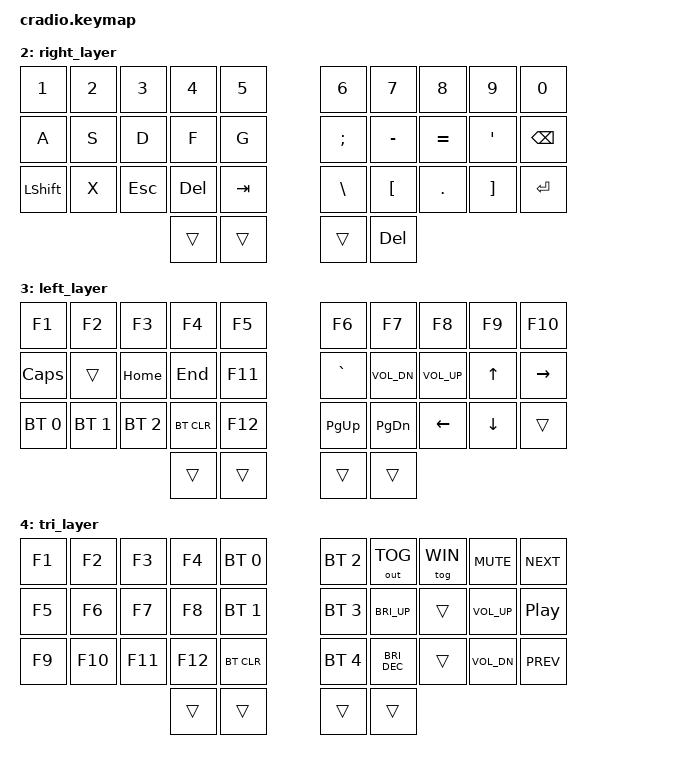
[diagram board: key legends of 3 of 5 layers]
// Copyright (c) 2022 The ZMK Contributors
// SPDX-License-Identifier: MIT

#include <behaviors.dtsi>
#include <dt-bindings/zmk/keys.h>
#include <dt-bindings/zmk/bt.h>
#include <dt-bindings/zmk/outputs.h>

// Home row mods macro
#define HRML(k2,k3,k4) &ht LCTRL k2  &ht LGUI k3  &ht LALT k4
#define HRMR(k1,k2,k3) &ht RALT k1  &ht RGUI k2  &ht RCTRL k3
#define MHRML(k2,k3,k4) &ht LGUI k2  &ht LCTRL k3  &ht LALT k4
#define MHRMR(k1,k2,k3) &ht RALT k1  &ht RCTRL k2  &ht RGUI k3

#define WIN 0
#define MAC 1
#define RIG 2
#define LEF 3
#define TRI 4

/ {
    behaviors {
        ht: hold_tap {
            label = "hold_tap";
            compatible = "zmk,behavior-hold-tap";
            #binding-cells = <2>;
            flavor = "tap-preferred";
            tapping-term-ms = <250>;
            quick-tap-ms = <125>;
            global-quick-tap;
            bindings = <&kp>, <&kp>;
        };
    };

    conditional_layers {
        compatible = "zmk,conditional-layers";
        tri_layer {
            if-layers = <RIG LEF>;
            then-layer = <TRI>;
        };
    };

    keymap {
        compatible = "zmk,keymap";
        default_layer {
            bindings = <
        //╭──────────┬──────────┬──────────┬──────────┬──────────╮   ╭──────────┬──────────┬──────────┬──────────┬──────────╮
        //│  Q       │  W       │  E       │  R       │  T       │   │  Y       │  U       │  I       │  O       │  P       │
            &kp Q      &kp W      &kp E      &kp R      &kp T          &kp Y      &kp U      &kp I      &kp O      &kp P
        //├──────────┼──────────┼──────────┼──────────┼──────────┤   ├──────────┼──────────┼──────────┼──────────┼──────────┤
        //│  A       │  S       │  D       │ F        │  G       │   │  H       │  J       │  K       │  L       │BACKSPACE│
            &kp A       &kp S      &kp D      &kp F      &kp G          &kp H      HRMR(J,        K,           L)   &kp BSPC
        //├──────────┼──────────┼──────────┼──────────┼──────────┤   ├──────────┼──────────┼──────────┼──────────┼──────────┤
        //│  Z       │  X       │  C       │  V       │  B       │   │  N       │  M       │ , <      │ / ？      │ ENTER SHIFT   │
            HRML(Z,        X,           C)          &kp V      &kp B          &kp N      &kp M      &kp COMMA  &kp SLASH    &ht RSHIFT ENTER 
        //╰──────────┴──────────┴──────────┼──────────┼──────────┤   ├──────────┼──────────┼──────────┴──────────┴──────────╯
                                           &kp SPACE          &mo RIG                 &mo RIG       &mo LEF
        //                                 ╰──────────┴──────────╯   ╰──────────┴──────────╯
            >;
        };

        mac_layer {
            bindings = <
        //╭──────────┬──────────┬──────────┬──────────┬──────────╮   ╭──────────┬──────────┬──────────┬──────────┬──────────╮
        //│  Q       │  W       │  E       │  R       │  T       │   │  Y       │  U       │  I       │  O       │  P       │
            &kp Q      &kp W      &kp E      &kp R      &kp T          &kp Y      &kp U      &kp I      &kp O      &kp P
        //├──────────┼──────────┼──────────┼──────────┼──────────┤   ├──────────┼──────────┼──────────┼──────────┼──────────┤
        //│  A       │  S       │  D       │ F       │  G       │   │  H       │  J       │  K       │  L       │BACKSPACE │
            &kp A       &kp S      &kp D      &kp F      &kp G          &kp H      MHRMR(J,        K,           L)   &kp BSPC
        //├──────────┼──────────┼──────────┼──────────┼──────────┤   ├──────────┼──────────┼──────────┼──────────┼──────────┤
        //│  Z       │  X       │  C       │  V       │  B       │   │  N       │  M       │ , <      │ / ？      │ ENTER SHIFT    │
            MHRML(Z,        X,           C)          &kp V      &kp B          &kp N      &kp M      &kp COMMA  &kp SLASH    &ht RSHIFT ENTER
        //╰──────────┴──────────┴──────────┼──────────┼──────────┤   ├──────────┼──────────┼──────────┴──────────┴──────────╯
                                           &kp SPACE          &mo RIG                 &mo RIG       &mo LEF
        //                                 ╰──────────┴──────────╯   ╰──────────┴──────────╯
            >;
        };

        right_layer {
            bindings = <
        //╭──────────┬──────────┬──────────┬──────────┬──────────╮   ╭──────────┬──────────┬──────────┬──────────┬──────────╮
        //│ 1        │  2       │  3       │  4       │  5       │   │ 6        │ 7        │ 8        │ 9        │   0      │
            &kp N1    &kp N2     &kp N3     &kp N4     &kp N5          &kp N6     &kp N7     &kp N8     &kp N9      &kp N0
        //├──────────┼──────────┼──────────┼──────────┼──────────┤   ├──────────┼──────────┼──────────┼──────────┼──────────┤
        //│A        │ S        │ D        │  F       │  G        |   │  ; :       │ - _   │ = +       | ' "      │ BACKSPACE    │
            &kp A       &kp S       &kp D       &kp F        &kp G          &kp SEMI   &kp MINUS   &kp EQUAL  &kp SQT  &kp BSPC
        //├──────────┼──────────┼──────────┼──────────┼──────────┤   ├──────────┼──────────┼──────────┼──────────┼──────────┤
        //│SHIFT │  X       │ ESC        │DELETE     │  TAB        │   │ \ |      │ [ {        │ .>      │ ] }       │ ENTER     │
            &kp LSHIFT   &kp X       &kp ESC       &kp DEL     &kp TAB           &kp BSLH    &kp LBKT   &kp DOT  &kp RBKT  &kp ENTER 
        //╰──────────┴──────────┴──────────┼──────────┼──────────┤   ├──────────┼──────────┼──────────┴──────────┴──────────╯
                                             &trans             &trans                       &trans     &kp DEL
        //                                 ╰──────────┴──────────╯   ╰──────────┴──────────╯
            >;
        };

        left_layer { 
            bindings = <
        //╭──────────┬──────────┬──────────┬───────────┬────────────╮   ╭────────────┬────────────┬──────────┬───────────┬──────────╮
        //│  F1      │  F2      │  F3      │  F4       │ F5                     │   │ F6         │ F7                  │ F8         │ F9           │F10            │
            &kp F1     &kp F2     &kp F3     &kp F4     &kp F5     &kp F6     &kp F7     &kp F8        &kp F9     &kp F10
        //├──────────┼──────────┼──────────┼───────────┼────────────┤   ├────────────┼────────────┼──────────┼───────────┼──────────┤
        //│ CAPSLOCK│           │ HOME    │ END        │ F11        │   │ ` ~       │ VOL_DOWN   │ VOL_UP  │ UP        │  RIGHT        │
            &kp CAPS   &trans  &kp HOME  &kp END  &kp F11 &kp GRAVE   &kp C_VOL_DN   &kp C_VOL_UP   &kp UP  &kp RIGHT
        //├──────────┼──────────┼──────────┼───────────┼────────────┤   ├────────────┼────────────┼──────────┼───────────┼──────────┤
        //│ PROFILE 0 │PROFILE 1 │ PROFILE 2│ CLEAR BT │ F12 │   │PAGE_UP     │ PAGE_DOWN    │ LEFT        |  DOWN    │                │
            &bt BT_SEL 0 &bt BT_SEL 1   &bt BT_SEL 2 &bt BT_CLR &kp F12     &kp PG_UP   &kp PG_DN     &kp LEFT      &kp DOWN      &trans 
        //╰──────────┴──────────┴──────────┼───────────┼────────────┤   ├────────────┼────────────┼──────────┴───────────┴──────────╯
                                                &trans     &trans         &trans     &trans
        //                                  ╰───────────┴──────────╯   ╰──────────┴────────────╯
            >;
        };

        tri_layer {
            bindings = <
        //╭──────────┬──────────┬──────────┬───────────┬────────────╮   ╭────────────┬────────────┬──────────┬───────────┬──────────╮
        //│  F1      │  F2      │  F3      │  F4       │ PROFILE 0  │   │ PROFILE 2  │ TOGGLEOUT  │ WINDOWS  │ VOL MUTE  │ NEXTSONG │
            &kp F1     &kp F2     &kp F3     &kp F4     &bt BT_SEL 0     &bt BT_SEL 2  &out OUT_TOG &tog WIN  &kp C_MUTE  &kp C_NEXT
        //├──────────┼──────────┼──────────┼───────────┼────────────┤   ├────────────┼────────────┼──────────┼───────────┼──────────┤
        //│  F5      │  F6      │  F7      │  F8       │ PROFILE 1  │   │ PROFILE 3  │ INC BRIGHT │          │  VOL UP   │PAUSEMUSIC│
            &kp F5     &kp F6     &kp F7     &kp F8     &bt BT_SEL 1     &bt BT_SEL 3  &kp C_BRI_UP  &trans   &kp C_VOL_UP  &kp C_PP
        //├──────────┼──────────┼──────────┼───────────┼────────────┤   ├────────────┼────────────┼──────────┼───────────┼──────────┤
        //│  F9      │  F10     │  F11     │  F12      │  CLEAR BT  │   │ PROFILE 4  │ DEC BRIGHT │          |  VOL DOWN │ PREVSONG │
            &kp F9     &kp F10    &kp F11    &kp F12     &bt BT_CLR      &bt BT_SEL 4  &kp C_BRI_DEC  &trans   &kp C_VOL_DN &kp C_PREV
        //╰──────────┴──────────┴──────────┼───────────┼────────────┤   ├────────────┼────────────┼──────────┴───────────┴──────────╯
                                                &trans     &trans         &trans     &trans
        //                                  ╰───────────┴──────────╯   ╰──────────┴────────────╯
            >;
        };
    };
};
